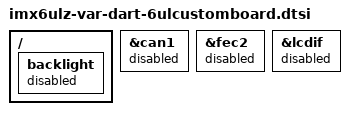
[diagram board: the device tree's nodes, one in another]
/*
 * Copyright (C) 2019 Variscite Ltd. - https://www.variscite.com
 *
 * This program is free software; you can redistribute it and/or modify
 * it under the terms of the GNU General Public License version 2 as
 * published by the Free Software Foundation.
 */

#include "imx6ull-var-dart-6ulcustomboard.dtsi"

/ {
	backlight {
		status = "disabled";
	};
};

&can1 {
	status = "disabled";
};

&fec2 {
	status = "disabled";
};

&lcdif {
	status = "disabled";
};
